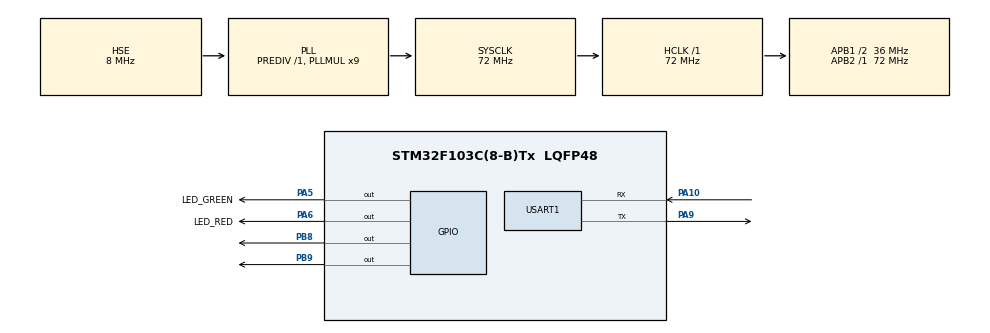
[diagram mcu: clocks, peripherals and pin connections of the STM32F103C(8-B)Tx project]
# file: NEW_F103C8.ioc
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Mcu.Family=STM32F1
Mcu.Name=STM32F103C(8-B)Tx
Mcu.Package=LQFP48
NVIC.PriorityGroup=NVIC_PRIORITYGROUP_4
PA10.Mode=Asynchronous
PA10.Signal=USART1_RX
PA13.Mode=Serial_Wire
PA13.Signal=SYS_JTMS-SWDIO
PA14.Mode=Serial_Wire
PA14.Signal=SYS_JTCK-SWCLK
PA5.GPIO_Label=LED_GREEN
PA5.GPIO_PuPd=GPIO_PULLUP
PA5.PinState=GPIO_PIN_SET
PA5.Signal=GPIO_Output
PA6.GPIO_Label=LED_RED
PA6.GPIO_PuPd=GPIO_PULLUP
PA6.PinState=GPIO_PIN_SET
PA6.Signal=GPIO_Output
PA9.Mode=Asynchronous
PA9.Signal=USART1_TX
PB8.GPIO_PuPd=GPIO_PULLUP
PB8.PinState=GPIO_PIN_SET
PB8.Signal=GPIO_Output
PB9.GPIO_PuPd=GPIO_PULLUP
PB9.PinState=GPIO_PIN_RESET
PB9.Signal=GPIO_Output
PD0-OSC_IN.Mode=HSE-External-Oscillator
PD0-OSC_IN.Signal=RCC_OSC_IN
PD1-OSC_OUT.Mode=HSE-External-Oscillator
PD1-OSC_OUT.Signal=RCC_OSC_OUT
ProjectManager.HeapSize=0x200
ProjectManager.StackSize=0x400
ProjectManager.TargetToolchain=MDK-ARM V5.27
RCC.AHBFreq_Value=72000000
RCC.APB1CLKDivider=RCC_HCLK_DIV2
RCC.APB1Freq_Value=36000000
RCC.APB1TimFreq_Value=72000000
RCC.APB2Freq_Value=72000000
RCC.APB2TimFreq_Value=72000000
RCC.HCLKFreq_Value=72000000
RCC.PLLMUL=RCC_PLL_MUL9
RCC.PLLSourceVirtual=RCC_PLLSOURCE_HSE
RCC.SYSCLKFreq_VALUE=72000000
RCC.SYSCLKSource=RCC_SYSCLKSOURCE_PLLCLK
RCC.USBFreq_Value=72000000
USART1.VirtualMode=VM_ASYNC
board=custom

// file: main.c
/* USER CODE BEGIN Header */
/**
  ******************************************************************************
  * @file           : main.c
  * @brief          : Main program body
  ******************************************************************************
  * @attention
  *
  * <h2><center>&copy; Copyright (c) 2020 STMicroelectronics.
  * All rights reserved.</center></h2>
  *
  * This software component is licensed by ST under BSD 3-Clause license,
  * the "License"; You may not use this file except in compliance with the
  * License. You may obtain a copy of the License at:
  *                        opensource.org/licenses/BSD-3-Clause
  *
  ******************************************************************************
  */
/* USER CODE END Header */

#include "main.h"
#include "usart.h"
#include "gpio.h"

/* USER CODE BEGIN Includes */
#include "IIC.h"
#include "mpu6050.h"
#include "inv_mpu.h"
#include "inv_mpu_dmp_motion_driver.h"
/* USER CODE END Includes */

void SystemClock_Config(void);

int main(void)
{
    /* USER CODE BEGIN 1 */
    float pitch,roll,yaw; 		//欧拉角
    short aacx,aacy,aacz;			//加速度传感器原始数据
    short gyrox,gyroy,gyroz;		//陀螺仪原始数据
    short temp;					//温度
    /* USER CODE END 1 */

    /* MCU Configuration--------------------------------------------------------*/

    /* Reset of all peripherals, Initializes the Flash interface and the Systick. */
    HAL_Init();

    /* Configure the system clock */
    SystemClock_Config();

    /* Initialize all configured peripherals */
    MX_GPIO_Init();
    MX_USART1_UART_Init();
    /* USER CODE BEGIN 2 */

    MPU_Init();			//MPU6050初始化
    mpu_dmp_init();		//dmp初始化

    /* USER CODE END 2 */

    /* Infinite loop */
    /* USER CODE BEGIN WHILE */
    while (1)
    {
        //HAL_Delay(500);
        while(mpu_dmp_get_data(&pitch, &roll, &yaw));	//必须要用while等待，才能读取成功

        MPU_Get_Accelerometer(&aacx,&aacy, &aacz);		//得到加速度传感器数据
        MPU_Get_Gyroscope(&gyrox, &gyroy, &gyroz);		//得到陀螺仪数据
        temp=MPU_Get_Temperature();						//得到温度信息
        //printf("%f", (pitch*10));							//串口1输出pitch信息
        /* USER CODE END WHILE */

    }
}

void SystemClock_Config(void)
{
    RCC_OscInitTypeDef RCC_OscInitStruct = {0};
    RCC_ClkInitTypeDef RCC_ClkInitStruct = {0};

    /** Initializes the CPU, AHB and APB busses clocks
    */
    RCC_OscInitStruct.OscillatorType = RCC_OSCILLATORTYPE_HSE;
    RCC_OscInitStruct.HSEState = RCC_HSE_ON;
    RCC_OscInitStruct.HSEPredivValue = RCC_HSE_PREDIV_DIV1;
    RCC_OscInitStruct.HSIState = RCC_HSI_ON;
    RCC_OscInitStruct.PLL.PLLState = RCC_PLL_ON;
    RCC_OscInitStruct.PLL.PLLSource = RCC_PLLSOURCE_HSE;
    RCC_OscInitStruct.PLL.PLLMUL = RCC_PLL_MUL9;
    if (HAL_RCC_OscConfig(&RCC_OscInitStruct) != HAL_OK)
    {
        Error_Handler();
    }
    /** Initializes the CPU, AHB and APB busses clocks
    */
    RCC_ClkInitStruct.ClockType = RCC_CLOCKTYPE_HCLK|RCC_CLOCKTYPE_SYSCLK
                                  |RCC_CLOCKTYPE_PCLK1|RCC_CLOCKTYPE_PCLK2;
    RCC_ClkInitStruct.SYSCLKSource = RCC_SYSCLKSOURCE_PLLCLK;
    RCC_ClkInitStruct.AHBCLKDivider = RCC_SYSCLK_DIV1;
    RCC_ClkInitStruct.APB1CLKDivider = RCC_HCLK_DIV2;
    RCC_ClkInitStruct.APB2CLKDivider = RCC_HCLK_DIV1;

    if (HAL_RCC_ClockConfig(&RCC_ClkInitStruct, FLASH_LATENCY_2) != HAL_OK)
    {
        Error_Handler();
    }
}

void Error_Handler(void)
{
}

/************************ (C) COPYRIGHT STMicroelectronics *****END OF FILE****/
